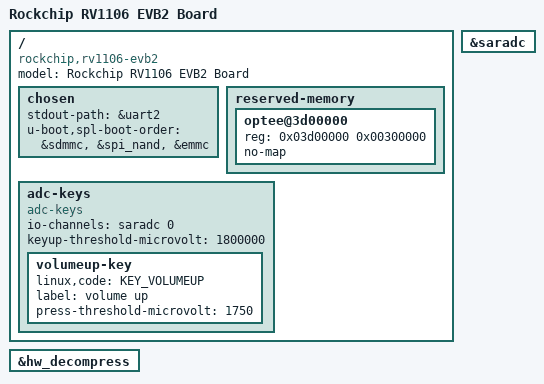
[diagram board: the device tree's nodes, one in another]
// SPDX-License-Identifier: (GPL-2.0+ OR MIT)
/*
 * Copyright (c) 2022 Rockchip Electronics Co., Ltd.
 */

/dts-v1/;

#include "rv1106.dtsi"
#include "rv1106-u-boot.dtsi"
#include <dt-bindings/input/input.h>

/ {
	model = "Rockchip RV1106 EVB2 Board";
	compatible = "rockchip,rv1106-evb2", "rockchip,rv1106";

	chosen {
		stdout-path = &uart2;
		u-boot,spl-boot-order = &sdmmc, &spi_nand, &emmc;
	};

	reserved-memory {
	#address-cells = <1>;
	#size-cells = <1>;
	ranges;

		/* OP-TEE secure RAM */
		optee@3d00000 {
			reg = <0x03d00000 0x00300000>; /* 3 MiB: 0x03D00000..0x04000000 */
			no-map;
		};
	};

	adc-keys {
		compatible = "adc-keys";
		io-channels = <&saradc 0>;
		io-channel-names = "buttons";
		keyup-threshold-microvolt = <1800000>;
		u-boot,dm-spl;
		status = "okay";

		volumeup-key {
			u-boot,dm-spl;
			linux,code = <KEY_VOLUMEUP>;
			label = "volume up";
			press-threshold-microvolt = <1750>;
		};

	};
};

&hw_decompress {
	u-boot,dm-spl;
	status = "okay";
};

&saradc {
	u-boot,dm-spl;
	status = "okay";
};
